VERSION ""

NS_ :

BS_:

BU_: BCU CCU Charger Charging_SDC DGPS DTI_Inverter Dash_Panel Debugger ECU Energy_Meter Fan_Controller_1 Fan_Controller_2 Fan_Controller_3 GR_Inverter IMD SAMM_Mag_1 SAMM_Mag_2 SAMM_ToF_1 SAMM_ToF_2 TCM TireTemp_FL TireTemp_FR TireTemp_RL TireTemp_RR ALL

BO_ 2147680257 BCU_Debug_2_0_to_Debugger: 8 BCU
 SG_ Debug : 0|64@1- (1,0) [0|0] "" Debugger

BO_ 2147680769 BCU_Ping_to_Debugger: 4 BCU
 SG_ Timestamp : 0|32@1+ (1,0) [0|4,294,967,296] "ms" Debugger

BO_ 2147680770 BCU_Ping_to_ECU: 4 BCU
 SG_ Timestamp : 0|32@1+ (1,0) [0|4,294,967,296] "ms" ECU

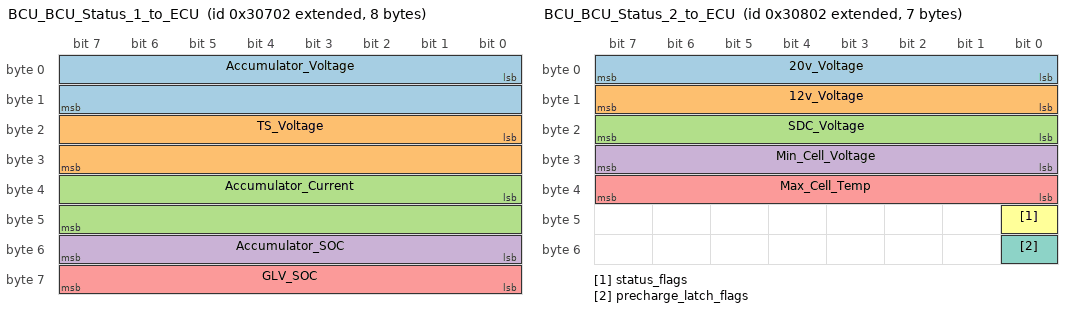
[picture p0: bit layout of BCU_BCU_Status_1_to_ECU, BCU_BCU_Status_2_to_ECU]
BO_ 2147682050 BCU_BCU_Status_1_to_ECU: 8 BCU
 SG_ Accumulator_Voltage : 0|16@1+ (0.01,0) [0|655.35] "Volts" ECU
 SG_ TS_Voltage : 16|16@1+ (0.01,0) [0|655.35] "Volts" ECU
 SG_ Accumulator_Current : 32|16@1- (0.01,0) [-327.68|327.67] "Amps" ECU
 SG_ Accumulator_SOC : 48|8@1+ (0.392157,0) [0|100] "%" ECU
 SG_ GLV_SOC : 56|8@1+ (0.392157,0) [0|100] "%" ECU

BO_ 2147682306 BCU_BCU_Status_2_to_ECU: 7 BCU
 SG_ 20v_Voltage : 0|8@1+ (1,0) [0|0] "" ECU
 SG_ 12v_Voltage : 8|8@1+ (1,0) [0|0] "" ECU
 SG_ SDC_Voltage : 16|8@1+ (1,0) [0|0] "" ECU
 SG_ Min_Cell_Voltage : 24|8@1+ (1,0) [0|0] "" ECU
 SG_ Max_Cell_Temp : 32|8@1+ (1,0) [0|0] "" ECU
 SG_ status_flags : 40|1@1+ (1,0) [0|0] "" ECU
 SG_ precharge_latch_flags : 48|1@1+ (1,0) [0|0] "" ECU

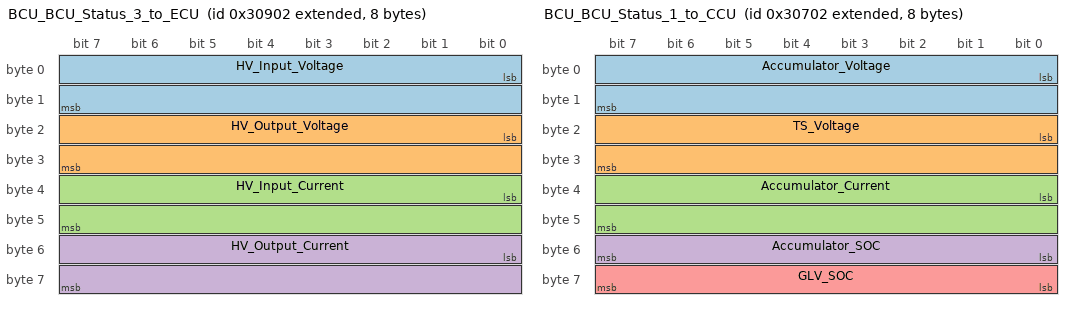
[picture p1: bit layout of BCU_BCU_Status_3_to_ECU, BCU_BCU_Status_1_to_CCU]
BO_ 2147682562 BCU_BCU_Status_3_to_ECU: 8 BCU
 SG_ HV_Input_Voltage : 0|16@1+ (0.01,0) [0|655.35] "Volts" ECU
 SG_ HV_Output_Voltage : 16|16@1+ (0.01,0) [0|655.35] "Volts" ECU
 SG_ HV_Input_Current : 32|16@1+ (0.001,0) [0|65.535] "Amps" ECU
 SG_ HV_Output_Current : 48|16@1+ (0.001,0) [0|65.535] "Amps" ECU

BO_ 2147680513 BCU_Debug_FD_to_Debugger: 64 BCU
 SG_ Debug : 0|64@1- (1,0) [0|0] "" Debugger

BO_ 2147680769 BCU_Ping_to_Debugger: 4 BCU
 SG_ Timestamp : 0|32@1+ (1,0) [0|4,294,967,296] "ms" Debugger

BO_ 2147680770 BCU_Ping_to_ECU: 4 BCU
 SG_ Timestamp : 0|32@1+ (1,0) [0|4,294,967,296] "ms" ECU

BO_ 2147683586 BCU_BCU_Cell_Data_1_to_ECU: 64 BCU
 SG_ Cell_0_Voltage : 0|8@1+ (0.01,2) [2|4.55] "Volts" ECU
 SG_ Cell_0_Temp : 8|8@1+ (0.25,0) [0|63.75] "Celsius" ECU
 SG_ Cell_1_Voltage : 16|8@1+ (0.01,2) [2|4.55] "Volts" ECU
 SG_ Cell_1_Temp : 24|8@1+ (0.25,0) [0|63.75] "Celsius" ECU
 SG_ Cell_2_Voltage : 32|8@1+ (0.01,2) [2|4.55] "Volts" ECU
 SG_ Cell_2_Temp : 40|8@1+ (0.25,0) [0|63.75] "Celsius" ECU
 SG_ Cell_3_Voltage : 48|8@1+ (0.01,2) [2|4.55] "Volts" ECU
 SG_ Cell_3_Temp : 56|8@1+ (0.25,0) [0|63.75] "Celsius" ECU
 SG_ Cell_4_Voltage : 64|8@1+ (0.01,2) [2|4.55] "Volts" ECU
 SG_ Cell_4_Temp : 72|8@1+ (0.25,0) [0|63.75] "Celsius" ECU
 SG_ Cell_5_Voltage : 80|8@1+ (0.01,2) [2|4.55] "Volts" ECU
 SG_ Cell_5_Temp : 88|8@1+ (0.25,0) [0|63.75] "Celsius" ECU
 SG_ Cell_6_Voltage : 96|8@1+ (0.01,2) [2|4.55] "Volts" ECU
 SG_ Cell_6_Temp : 104|8@1+ (0.25,0) [0|63.75] "Celsius" ECU
 SG_ Cell_7_Voltage : 112|8@1+ (0.01,2) [2|4.55] "Volts" ECU
 SG_ Cell_7_Temp : 120|8@1+ (0.25,0) [0|63.75] "Celsius" ECU
 SG_ Cell_8_Voltage : 128|8@1+ (0.01,2) [2|4.55] "Volts" ECU
 SG_ Cell_8_Temp : 136|8@1+ (0.25,0) [0|63.75] "Celsius" ECU
 SG_ Cell_9_Voltage : 144|8@1+ (0.01,2) [2|4.55] "Volts" ECU
 SG_ Cell_9_Temp : 152|8@1+ (0.25,0) [0|63.75] "Celsius" ECU
 SG_ Cell_10_Voltage : 160|8@1+ (0.01,2) [2|4.55] "Volts" ECU
 SG_ Cell_10_Temp : 168|8@1+ (0.25,0) [0|63.75] "Celsius" ECU
 SG_ Cell_11_Voltage : 176|8@1+ (0.01,2) [2|4.55] "Volts" ECU
 SG_ Cell_11_Temp : 184|8@1+ (0.25,0) [0|63.75] "Celsius" ECU
 SG_ Cell_12_Voltage : 192|8@1+ (0.01,2) [2|4.55] "Volts" ECU
 SG_ Cell_12_Temp : 200|8@1+ (0.25,0) [0|63.75] "Celsius" ECU
 SG_ Cell_13_Voltage : 208|8@1+ (0.01,2) [2|4.55] "Volts" ECU
 SG_ Cell_13_Temp : 216|8@1+ (0.25,0) [0|63.75] "Celsius" ECU
 SG_ Cell_14_Voltage : 224|8@1+ (0.01,2) [2|4.55] "Volts" ECU
 SG_ Cell_14_Temp : 232|8@1+ (0.25,0) [0|63.75] "Celsius" ECU
 SG_ Cell_15_Voltage : 240|8@1+ (0.01,2) [2|4.55] "Volts" ECU
 SG_ Cell_15_Temp : 248|8@1+ (0.25,0) [0|63.75] "Celsius" ECU
 SG_ Cell_16_Voltage : 256|8@1+ (0.01,2) [2|4.55] "Volts" ECU
 SG_ Cell_16_Temp : 264|8@1+ (0.25,0) [0|63.75] "Celsius" ECU
 SG_ Cell_17_Voltage : 272|8@1+ (0.01,2) [2|4.55] "Volts" ECU
 SG_ Cell_17_Temp : 280|8@1+ (0.25,0) [0|63.75] "Celsius" ECU
 SG_ Cell_18_Voltage : 288|8@1+ (0.01,2) [2|4.55] "Volts" ECU
 SG_ Cell_18_Temp : 296|8@1+ (0.25,0) [0|63.75] "Celsius" ECU
 SG_ Cell_19_Voltage : 304|8@1+ (0.01,2) [2|4.55] "Volts" ECU
 SG_ Cell_19_Temp : 312|8@1+ (0.25,0) [0|63.75] "Celsius" ECU
 SG_ Cell_20_Voltage : 320|8@1+ (0.01,2) [2|4.55] "Volts" ECU
 SG_ Cell_20_Temp : 328|8@1+ (0.25,0) [0|63.75] "Celsius" ECU
 SG_ Cell_21_Voltage : 336|8@1+ (0.01,2) [2|4.55] "Volts" ECU
 SG_ Cell_21_Temp : 344|8@1+ (0.25,0) [0|63.75] "Celsius" ECU
 SG_ Cell_22_Voltage : 352|8@1+ (0.01,2) [2|4.55] "Volts" ECU
 SG_ Cell_22_Temp : 360|8@1+ (0.25,0) [0|63.75] "Celsius" ECU
 SG_ Cell_23_Voltage : 368|8@1+ (0.01,2) [2|4.55] "Volts" ECU
 SG_ Cell_23_Temp : 376|8@1+ (0.25,0) [0|63.75] "Celsius" ECU
 SG_ Cell_24_Voltage : 384|8@1+ (0.01,2) [2|4.55] "Volts" ECU
 SG_ Cell_24_Temp : 392|8@1+ (0.25,0) [0|63.75] "Celsius" ECU
 SG_ Cell_25_Voltage : 400|8@1+ (0.01,2) [2|4.55] "Volts" ECU
 SG_ Cell_25_Temp : 408|8@1+ (0.25,0) [0|63.75] "Celsius" ECU
 SG_ Cell_26_Voltage : 416|8@1+ (0.01,2) [2|4.55] "Volts" ECU
 SG_ Cell_26_Temp : 424|8@1+ (0.25,0) [0|63.75] "Celsius" ECU
 SG_ Cell_27_Voltage : 432|8@1+ (0.01,2) [2|4.55] "Volts" ECU
 SG_ Cell_27_Temp : 440|8@1+ (0.25,0) [0|63.75] "Celsius" ECU
 SG_ Cell_28_Voltage : 448|8@1+ (0.01,2) [2|4.55] "Volts" ECU
 SG_ Cell_28_Temp : 456|8@1+ (0.25,0) [0|63.75] "Celsius" ECU
 SG_ Cell_29_Voltage : 464|8@1+ (0.01,2) [2|4.55] "Volts" ECU
 SG_ Cell_29_Temp : 472|8@1+ (0.25,0) [0|63.75] "Celsius" ECU
 SG_ Cell_30_Voltage : 480|8@1+ (0.01,2) [2|4.55] "Volts" ECU
 SG_ Cell_30_Temp : 488|8@1+ (0.25,0) [0|63.75] "Celsius" ECU
 SG_ Cell_31_Voltage : 496|8@1+ (0.01,2) [2|4.55] "Volts" ECU
 SG_ Cell_31_Temp : 504|8@1+ (0.25,0) [0|63.75] "Celsius" ECU

BO_ 2147683842 BCU_BCU_Cell_Data_2_to_ECU: 64 BCU
 SG_ Cell_32_Voltage : 0|8@1+ (0.01,2) [2|4.55] "Volts" ECU
 SG_ Cell_32_Temp : 8|8@1+ (0.25,0) [0|63.75] "Celsius" ECU
 SG_ Cell_33_Voltage : 16|8@1+ (0.01,2) [2|4.55] "Volts" ECU
 SG_ Cell_33_Temp : 24|8@1+ (0.25,0) [0|63.75] "Celsius" ECU
 SG_ Cell_34_Voltage : 32|8@1+ (0.01,2) [2|4.55] "Volts" ECU
 SG_ Cell_34_Temp : 40|8@1+ (0.25,0) [0|63.75] "Celsius" ECU
 SG_ Cell_35_Voltage : 48|8@1+ (0.01,2) [2|4.55] "Volts" ECU
 SG_ Cell_35_Temp : 56|8@1+ (0.25,0) [0|63.75] "Celsius" ECU
 SG_ Cell_36_Voltage : 64|8@1+ (0.01,2) [2|4.55] "Volts" ECU
 SG_ Cell_36_Temp : 72|8@1+ (0.25,0) [0|63.75] "Celsius" ECU
 SG_ Cell_37_Voltage : 80|8@1+ (0.01,2) [2|4.55] "Volts" ECU
 SG_ Cell_37_Temp : 88|8@1+ (0.25,0) [0|63.75] "Celsius" ECU
 SG_ Cell_38_Voltage : 96|8@1+ (0.01,2) [2|4.55] "Volts" ECU
 SG_ Cell_38_Temp : 104|8@1+ (0.25,0) [0|63.75] "Celsius" ECU
 SG_ Cell_39_Voltage : 112|8@1+ (0.01,2) [2|4.55] "Volts" ECU
 SG_ Cell_39_Temp : 120|8@1+ (0.25,0) [0|63.75] "Celsius" ECU
 SG_ Cell_40_Voltage : 128|8@1+ (0.01,2) [2|4.55] "Volts" ECU
 SG_ Cell_40_Temp : 136|8@1+ (0.25,0) [0|63.75] "Celsius" ECU
 SG_ Cell_41_Voltage : 144|8@1+ (0.01,2) [2|4.55] "Volts" ECU
 SG_ Cell_41_Temp : 152|8@1+ (0.25,0) [0|63.75] "Celsius" ECU
 SG_ Cell_42_Voltage : 160|8@1+ (0.01,2) [2|4.55] "Volts" ECU
 SG_ Cell_42_Temp : 168|8@1+ (0.25,0) [0|63.75] "Celsius" ECU
 SG_ Cell_43_Voltage : 176|8@1+ (0.01,2) [2|4.55] "Volts" ECU
 SG_ Cell_43_Temp : 184|8@1+ (0.25,0) [0|63.75] "Celsius" ECU
 SG_ Cell_44_Voltage : 192|8@1+ (0.01,2) [2|4.55] "Volts" ECU
 SG_ Cell_44_Temp : 200|8@1+ (0.25,0) [0|63.75] "Celsius" ECU
 SG_ Cell_45_Voltage : 208|8@1+ (0.01,2) [2|4.55] "Volts" ECU
 SG_ Cell_45_Temp : 216|8@1+ (0.25,0) [0|63.75] "Celsius" ECU
 SG_ Cell_46_Voltage : 224|8@1+ (0.01,2) [2|4.55] "Volts" ECU
 SG_ Cell_46_Temp : 232|8@1+ (0.25,0) [0|63.75] "Celsius" ECU
 SG_ Cell_47_Voltage : 240|8@1+ (0.01,2) [2|4.55] "Volts" ECU
 SG_ Cell_47_Temp : 248|8@1+ (0.25,0) [0|63.75] "Celsius" ECU
 SG_ Cell_48_Voltage : 256|8@1+ (0.01,2) [2|4.55] "Volts" ECU
 SG_ Cell_48_Temp : 264|8@1+ (0.25,0) [0|63.75] "Celsius" ECU
 SG_ Cell_49_Voltage : 272|8@1+ (0.01,2) [2|4.55] "Volts" ECU
 SG_ Cell_49_Temp : 280|8@1+ (0.25,0) [0|63.75] "Celsius" ECU
 SG_ Cell_50_Voltage : 288|8@1+ (0.01,2) [2|4.55] "Volts" ECU
 SG_ Cell_50_Temp : 296|8@1+ (0.25,0) [0|63.75] "Celsius" ECU
 SG_ Cell_51_Voltage : 304|8@1+ (0.01,2) [2|4.55] "Volts" ECU
 SG_ Cell_51_Temp : 312|8@1+ (0.25,0) [0|63.75] "Celsius" ECU
 SG_ Cell_52_Voltage : 320|8@1+ (0.01,2) [2|4.55] "Volts" ECU
 SG_ Cell_52_Temp : 328|8@1+ (0.25,0) [0|63.75] "Celsius" ECU
 SG_ Cell_53_Voltage : 336|8@1+ (0.01,2) [2|4.55] "Volts" ECU
 SG_ Cell_53_Temp : 344|8@1+ (0.25,0) [0|63.75] "Celsius" ECU
 SG_ Cell_54_Voltage : 352|8@1+ (0.01,2) [2|4.55] "Volts" ECU
 SG_ Cell_54_Temp : 360|8@1+ (0.25,0) [0|63.75] "Celsius" ECU
 SG_ Cell_55_Voltage : 368|8@1+ (0.01,2) [2|4.55] "Volts" ECU
 SG_ Cell_55_Temp : 376|8@1+ (0.25,0) [0|63.75] "Celsius" ECU
 SG_ Cell_56_Voltage : 384|8@1+ (0.01,2) [2|4.55] "Volts" ECU
 SG_ Cell_56_Temp : 392|8@1+ (0.25,0) [0|63.75] "Celsius" ECU
 SG_ Cell_57_Voltage : 400|8@1+ (0.01,2) [2|4.55] "Volts" ECU
 SG_ Cell_57_Temp : 408|8@1+ (0.25,0) [0|63.75] "Celsius" ECU
 SG_ Cell_58_Voltage : 416|8@1+ (0.01,2) [2|4.55] "Volts" ECU
 SG_ Cell_58_Temp : 424|8@1+ (0.25,0) [0|63.75] "Celsius" ECU
 SG_ Cell_59_Voltage : 432|8@1+ (0.01,2) [2|4.55] "Volts" ECU
 SG_ Cell_59_Temp : 440|8@1+ (0.25,0) [0|63.75] "Celsius" ECU
 SG_ Cell_60_Voltage : 448|8@1+ (0.01,2) [2|4.55] "Volts" ECU
 SG_ Cell_60_Temp : 456|8@1+ (0.25,0) [0|63.75] "Celsius" ECU
 SG_ Cell_61_Voltage : 464|8@1+ (0.01,2) [2|4.55] "Volts" ECU
 SG_ Cell_61_Temp : 472|8@1+ (0.25,0) [0|63.75] "Celsius" ECU
 SG_ Cell_62_Voltage : 480|8@1+ (0.01,2) [2|4.55] "Volts" ECU
 SG_ Cell_62_Temp : 488|8@1+ (0.25,0) [0|63.75] "Celsius" ECU
 SG_ Cell_63_Voltage : 496|8@1+ (0.01,2) [2|4.55] "Volts" ECU
 SG_ Cell_63_Temp : 504|8@1+ (0.25,0) [0|63.75] "Celsius" ECU

BO_ 2147684098 BCU_BCU_Cell_Data_3_to_ECU: 64 BCU
 SG_ Cell_64_Voltage : 0|8@1+ (0.01,2) [2|4.55] "Volts" ECU
 SG_ Cell_64_Temp : 8|8@1+ (0.25,0) [0|63.75] "Celsius" ECU
 SG_ Cell_65_Voltage : 16|8@1+ (0.01,2) [2|4.55] "Volts" ECU
 SG_ Cell_65_Temp : 24|8@1+ (0.25,0) [0|63.75] "Celsius" ECU
 SG_ Cell_66_Voltage : 32|8@1+ (0.01,2) [2|4.55] "Volts" ECU
 SG_ Cell_66_Temp : 40|8@1+ (0.25,0) [0|63.75] "Celsius" ECU
 SG_ Cell_67_Voltage : 48|8@1+ (0.01,2) [2|4.55] "Volts" ECU
 SG_ Cell_67_Temp : 56|8@1+ (0.25,0) [0|63.75] "Celsius" ECU
 SG_ Cell_68_Voltage : 64|8@1+ (0.01,2) [2|4.55] "Volts" ECU
 SG_ Cell_68_Temp : 72|8@1+ (0.25,0) [0|63.75] "Celsius" ECU
 SG_ Cell_69_Voltage : 80|8@1+ (0.01,2) [2|4.55] "Volts" ECU
 SG_ Cell_69_Temp : 88|8@1+ (0.25,0) [0|63.75] "Celsius" ECU
 SG_ Cell_70_Voltage : 96|8@1+ (0.01,2) [2|4.55] "Volts" ECU
 SG_ Cell_70_Temp : 104|8@1+ (0.25,0) [0|63.75] "Celsius" ECU
 SG_ Cell_71_Voltage : 112|8@1+ (0.01,2) [2|4.55] "Volts" ECU
 SG_ Cell_71_Temp : 120|8@1+ (0.25,0) [0|63.75] "Celsius" ECU
 SG_ Cell_72_Voltage : 128|8@1+ (0.01,2) [2|4.55] "Volts" ECU
 SG_ Cell_72_Temp : 136|8@1+ (0.25,0) [0|63.75] "Celsius" ECU
 SG_ Cell_73_Voltage : 144|8@1+ (0.01,2) [2|4.55] "Volts" ECU
 SG_ Cell_73_Temp : 152|8@1+ (0.25,0) [0|63.75] "Celsius" ECU
 SG_ Cell_74_Voltage : 160|8@1+ (0.01,2) [2|4.55] "Volts" ECU
 SG_ Cell_74_Temp : 168|8@1+ (0.25,0) [0|63.75] "Celsius" ECU
 SG_ Cell_75_Voltage : 176|8@1+ (0.01,2) [2|4.55] "Volts" ECU
 SG_ Cell_75_Temp : 184|8@1+ (0.25,0) [0|63.75] "Celsius" ECU
 SG_ Cell_76_Voltage : 192|8@1+ (0.01,2) [2|4.55] "Volts" ECU
 SG_ Cell_76_Temp : 200|8@1+ (0.25,0) [0|63.75] "Celsius" ECU
 SG_ Cell_77_Voltage : 208|8@1+ (0.01,2) [2|4.55] "Volts" ECU
 SG_ Cell_77_Temp : 216|8@1+ (0.25,0) [0|63.75] "Celsius" ECU
 SG_ Cell_78_Voltage : 224|8@1+ (0.01,2) [2|4.55] "Volts" ECU
 SG_ Cell_78_Temp : 232|8@1+ (0.25,0) [0|63.75] "Celsius" ECU
 SG_ Cell_79_Voltage : 240|8@1+ (0.01,2) [2|4.55] "Volts" ECU
 SG_ Cell_79_Temp : 248|8@1+ (0.25,0) [0|63.75] "Celsius" ECU
 SG_ Cell_80_Voltage : 256|8@1+ (0.01,2) [2|4.55] "Volts" ECU
 SG_ Cell_80_Temp : 264|8@1+ (0.25,0) [0|63.75] "Celsius" ECU
 SG_ Cell_81_Voltage : 272|8@1+ (0.01,2) [2|4.55] "Volts" ECU
 SG_ Cell_81_Temp : 280|8@1+ (0.25,0) [0|63.75] "Celsius" ECU
 SG_ Cell_82_Voltage : 288|8@1+ (0.01,2) [2|4.55] "Volts" ECU
 SG_ Cell_82_Temp : 296|8@1+ (0.25,0) [0|63.75] "Celsius" ECU
 SG_ Cell_83_Voltage : 304|8@1+ (0.01,2) [2|4.55] "Volts" ECU
 SG_ Cell_83_Temp : 312|8@1+ (0.25,0) [0|63.75] "Celsius" ECU
 SG_ Cell_84_Voltage : 320|8@1+ (0.01,2) [2|4.55] "Volts" ECU
 SG_ Cell_84_Temp : 328|8@1+ (0.25,0) [0|63.75] "Celsius" ECU
 SG_ Cell_85_Voltage : 336|8@1+ (0.01,2) [2|4.55] "Volts" ECU
 SG_ Cell_85_Temp : 344|8@1+ (0.25,0) [0|63.75] "Celsius" ECU
 SG_ Cell_86_Voltage : 352|8@1+ (0.01,2) [2|4.55] "Volts" ECU
 SG_ Cell_86_Temp : 360|8@1+ (0.25,0) [0|63.75] "Celsius" ECU
 SG_ Cell_87_Voltage : 368|8@1+ (0.01,2) [2|4.55] "Volts" ECU
 SG_ Cell_87_Temp : 376|8@1+ (0.25,0) [0|63.75] "Celsius" ECU
 SG_ Cell_88_Voltage : 384|8@1+ (0.01,2) [2|4.55] "Volts" ECU
 SG_ Cell_88_Temp : 392|8@1+ (0.25,0) [0|63.75] "Celsius" ECU
 SG_ Cell_89_Voltage : 400|8@1+ (0.01,2) [2|4.55] "Volts" ECU
 SG_ Cell_89_Temp : 408|8@1+ (0.25,0) [0|63.75] "Celsius" ECU
 SG_ Cell_90_Voltage : 416|8@1+ (0.01,2) [2|4.55] "Volts" ECU
 SG_ Cell_90_Temp : 424|8@1+ (0.25,0) [0|63.75] "Celsius" ECU
 SG_ Cell_91_Voltage : 432|8@1+ (0.01,2) [2|4.55] "Volts" ECU
 SG_ Cell_91_Temp : 440|8@1+ (0.25,0) [0|63.75] "Celsius" ECU
 SG_ Cell_92_Voltage : 448|8@1+ (0.01,2) [2|4.55] "Volts" ECU
 SG_ Cell_92_Temp : 456|8@1+ (0.25,0) [0|63.75] "Celsius" ECU
 SG_ Cell_93_Voltage : 464|8@1+ (0.01,2) [2|4.55] "Volts" ECU
 SG_ Cell_93_Temp : 472|8@1+ (0.25,0) [0|63.75] "Celsius" ECU
 SG_ Cell_94_Voltage : 480|8@1+ (0.01,2) [2|4.55] "Volts" ECU
 SG_ Cell_94_Temp : 488|8@1+ (0.25,0) [0|63.75] "Celsius" ECU
 SG_ Cell_95_Voltage : 496|8@1+ (0.01,2) [2|4.55] "Volts" ECU
 SG_ Cell_95_Temp : 504|8@1+ (0.25,0) [0|63.75] "Celsius" ECU

BO_ 2147684354 BCU_BCU_Cell_Data_4_to_ECU: 64 BCU
 SG_ Cell_96_Voltage : 0|8@1+ (0.01,2) [2|4.55] "Volts" ECU
 SG_ Cell_96_Temp : 8|8@1+ (0.25,0) [0|63.75] "Celsius" ECU
 SG_ Cell_97_Voltage : 16|8@1+ (0.01,2) [2|4.55] "Volts" ECU
 SG_ Cell_97_Temp : 24|8@1+ (0.25,0) [0|63.75] "Celsius" ECU
 SG_ Cell_98_Voltage : 32|8@1+ (0.01,2) [2|4.55] "Volts" ECU
 SG_ Cell_98_Temp : 40|8@1+ (0.25,0) [0|63.75] "Celsius" ECU
 SG_ Cell_99_Voltage : 48|8@1+ (0.01,2) [2|4.55] "Volts" ECU
 SG_ Cell_99_Temp : 56|8@1+ (0.25,0) [0|63.75] "Celsius" ECU
 SG_ Cell_100_Voltage : 64|8@1+ (0.01,2) [2|4.55] "Volts" ECU
 SG_ Cell_100_Temp : 72|8@1+ (0.25,0) [0|63.75] "Celsius" ECU
 SG_ Cell_101_Voltage : 80|8@1+ (0.01,2) [2|4.55] "Volts" ECU
 SG_ Cell_101_Temp : 88|8@1+ (0.25,0) [0|63.75] "Celsius" ECU
 SG_ Cell_102_Voltage : 96|8@1+ (0.01,2) [2|4.55] "Volts" ECU
 SG_ Cell_102_Temp : 104|8@1+ (0.25,0) [0|63.75] "Celsius" ECU
 SG_ Cell_103_Voltage : 112|8@1+ (0.01,2) [2|4.55] "Volts" ECU
 SG_ Cell_103_Temp : 120|8@1+ (0.25,0) [0|63.75] "Celsius" ECU
 SG_ Cell_104_Voltage : 128|8@1+ (0.01,2) [2|4.55] "Volts" ECU
 SG_ Cell_104_Temp : 136|8@1+ (0.25,0) [0|63.75] "Celsius" ECU
 SG_ Cell_105_Voltage : 144|8@1+ (0.01,2) [2|4.55] "Volts" ECU
 SG_ Cell_105_Temp : 152|8@1+ (0.25,0) [0|63.75] "Celsius" ECU
 SG_ Cell_106_Voltage : 160|8@1+ (0.01,2) [2|4.55] "Volts" ECU
 SG_ Cell_106_Temp : 168|8@1+ (0.25,0) [0|63.75] "Celsius" ECU
 SG_ Cell_107_Voltage : 176|8@1+ (0.01,2) [2|4.55] "Volts" ECU
 SG_ Cell_107_Temp : 184|8@1+ (0.25,0) [0|63.75] "Celsius" ECU
 SG_ Cell_108_Voltage : 192|8@1+ (0.01,2) [2|4.55] "Volts" ECU
 SG_ Cell_108_Temp : 200|8@1+ (0.25,0) [0|63.75] "Celsius" ECU
 SG_ Cell_109_Voltage : 208|8@1+ (0.01,2) [2|4.55] "Volts" ECU
 SG_ Cell_109_Temp : 216|8@1+ (0.25,0) [0|63.75] "Celsius" ECU
 SG_ Cell_110_Voltage : 224|8@1+ (0.01,2) [2|4.55] "Volts" ECU
 SG_ Cell_110_Temp : 232|8@1+ (0.25,0) [0|63.75] "Celsius" ECU
 SG_ Cell_111_Voltage : 240|8@1+ (0.01,2) [2|4.55] "Volts" ECU
 SG_ Cell_111_Temp : 248|8@1+ (0.25,0) [0|63.75] "Celsius" ECU
 SG_ Cell_112_Voltage : 256|8@1+ (0.01,2) [2|4.55] "Volts" ECU
 SG_ Cell_112_Temp : 264|8@1+ (0.25,0) [0|63.75] "Celsius" ECU
 SG_ Cell_113_Voltage : 272|8@1+ (0.01,2) [2|4.55] "Volts" ECU
 SG_ Cell_113_Temp : 280|8@1+ (0.25,0) [0|63.75] "Celsius" ECU
 SG_ Cell_114_Voltage : 288|8@1+ (0.01,2) [2|4.55] "Volts" ECU
 SG_ Cell_114_Temp : 296|8@1+ (0.25,0) [0|63.75] "Celsius" ECU
 SG_ Cell_115_Voltage : 304|8@1+ (0.01,2) [2|4.55] "Volts" ECU
 SG_ Cell_115_Temp : 312|8@1+ (0.25,0) [0|63.75] "Celsius" ECU
 SG_ Cell_116_Voltage : 320|8@1+ (0.01,2) [2|4.55] "Volts" ECU
 SG_ Cell_116_Temp : 328|8@1+ (0.25,0) [0|63.75] "Celsius" ECU
 SG_ Cell_117_Voltage : 336|8@1+ (0.01,2) [2|4.55] "Volts" ECU
 SG_ Cell_117_Temp : 344|8@1+ (0.25,0) [0|63.75] "Celsius" ECU
 SG_ Cell_118_Voltage : 352|8@1+ (0.01,2) [2|4.55] "Volts" ECU
 SG_ Cell_118_Temp : 360|8@1+ (0.25,0) [0|63.75] "Celsius" ECU
 SG_ Cell_119_Voltage : 368|8@1+ (0.01,2) [2|4.55] "Volts" ECU
 SG_ Cell_119_Temp : 376|8@1+ (0.25,0) [0|63.75] "Celsius" ECU
 SG_ Cell_120_Voltage : 384|8@1+ (0.01,2) [2|4.55] "Volts" ECU
 SG_ Cell_120_Temp : 392|8@1+ (0.25,0) [0|63.75] "Celsius" ECU
 SG_ Cell_121_Voltage : 400|8@1+ (0.01,2) [2|4.55] "Volts" ECU
 SG_ Cell_121_Temp : 408|8@1+ (0.25,0) [0|63.75] "Celsius" ECU
 SG_ Cell_122_Voltage : 416|8@1+ (0.01,2) [2|4.55] "Volts" ECU
 SG_ Cell_122_Temp : 424|8@1+ (0.25,0) [0|63.75] "Celsius" ECU
 SG_ Cell_123_Voltage : 432|8@1+ (0.01,2) [2|4.55] "Volts" ECU
 SG_ Cell_123_Temp : 440|8@1+ (0.25,0) [0|63.75] "Celsius" ECU
 SG_ Cell_124_Voltage : 448|8@1+ (0.01,2) [2|4.55] "Volts" ECU
 SG_ Cell_124_Temp : 456|8@1+ (0.25,0) [0|63.75] "Celsius" ECU
 SG_ Cell_125_Voltage : 464|8@1+ (0.01,2) [2|4.55] "Volts" ECU
 SG_ Cell_125_Temp : 472|8@1+ (0.25,0) [0|63.75] "Celsius" ECU
 SG_ Cell_126_Voltage : 480|8@1+ (0.01,2) [2|4.55] "Volts" ECU
 SG_ Cell_126_Temp : 488|8@1+ (0.25,0) [0|63.75] "Celsius" ECU
 SG_ Cell_127_Voltage : 496|8@1+ (0.01,2) [2|4.55] "Volts" ECU
 SG_ Cell_127_Temp : 504|8@1+ (0.25,0) [0|63.75] "Celsius" ECU

BO_ 2147684610 BCU_BCU_Cell_Data_5_to_ECU: 64 BCU
 SG_ Cell_128_Voltage : 0|8@1+ (0.01,2) [2|4.55] "Volts" ECU
 SG_ Cell_128_Temp : 8|8@1+ (0.25,0) [0|63.75] "Celsius" ECU
 SG_ Cell_129_Voltage : 16|8@1+ (0.01,2) [2|4.55] "Volts" ECU
 SG_ Cell_129_Temp : 24|8@1+ (0.25,0) [0|63.75] "Celsius" ECU
 SG_ Cell_130_Voltage : 32|8@1+ (0.01,2) [2|4.55] "Volts" ECU
 SG_ Cell_130_Temp : 40|8@1+ (0.25,0) [0|63.75] "Celsius" ECU
 SG_ Cell_131_Voltage : 48|8@1+ (0.01,2) [2|4.55] "Volts" ECU
 SG_ Cell_131_Temp : 56|8@1+ (0.25,0) [0|63.75] "Celsius" ECU
 SG_ Cell_132_Voltage : 64|8@1+ (0.01,2) [2|4.55] "Volts" ECU
 SG_ Cell_132_Temp : 72|8@1+ (0.25,0) [0|63.75] "Celsius" ECU
 SG_ Cell_133_Voltage : 80|8@1+ (0.01,2) [2|4.55] "Volts" ECU
 SG_ Cell_133_Temp : 88|8@1+ (0.25,0) [0|63.75] "Celsius" ECU
 SG_ Cell_134_Voltage : 96|8@1+ (0.01,2) [2|4.55] "Volts" ECU
 SG_ Cell_134_Temp : 104|8@1+ (0.25,0) [0|63.75] "Celsius" ECU
 SG_ Cell_135_Voltage : 112|8@1+ (0.01,2) [2|4.55] "Volts" ECU
 SG_ Cell_135_Temp : 120|8@1+ (0.25,0) [0|63.75] "Celsius" ECU
 SG_ Cell_136_Voltage : 128|8@1+ (0.01,2) [2|4.55] "Volts" ECU
 SG_ Cell_136_Temp : 136|8@1+ (0.25,0) [0|63.75] "Celsius" ECU
 SG_ Cell_137_Voltage : 144|8@1+ (0.01,2) [2|4.55] "Volts" ECU
 SG_ Cell_137_Temp : 152|8@1+ (0.25,0) [0|63.75] "Celsius" ECU
 SG_ Cell_138_Voltage : 160|8@1+ (0.01,2) [2|4.55] "Volts" ECU
 SG_ Cell_138_Temp : 168|8@1+ (0.25,0) [0|63.75] "Celsius" ECU
 SG_ Cell_139_Voltage : 176|8@1+ (0.01,2) [2|4.55] "Volts" ECU
 SG_ Cell_139_Temp : 184|8@1+ (0.25,0) [0|63.75] "Celsius" ECU
 SG_ Cell_140_Voltage : 192|8@1+ (0.01,2) [2|4.55] "Volts" ECU
 SG_ Cell_140_Temp : 200|8@1+ (0.25,0) [0|63.75] "Celsius" ECU
 SG_ Cell_141_Voltage : 208|8@1+ (0.01,2) [2|4.55] "Volts" ECU
 SG_ Cell_141_Temp : 216|8@1+ (0.25,0) [0|63.75] "Celsius" ECU
 SG_ Cell_142_Voltage : 224|8@1+ (0.01,2) [2|4.55] "Volts" ECU
 SG_ Cell_142_Temp : 232|8@1+ (0.25,0) [0|63.75] "Celsius" ECU
 SG_ Cell_143_Voltage : 240|8@1+ (0.01,2) [2|4.55] "Volts" ECU
 SG_ Cell_143_Temp : 248|8@1+ (0.25,0) [0|63.75] "Celsius" ECU
 SG_ Cell_144_Voltage : 256|8@1+ (0.01,2) [2|4.55] "Volts" ECU
 SG_ Cell_144_Temp : 264|8@1+ (0.25,0) [0|63.75] "Celsius" ECU
 SG_ Cell_145_Voltage : 272|8@1+ (0.01,2) [2|4.55] "Volts" ECU
 SG_ Cell_145_Temp : 280|8@1+ (0.25,0) [0|63.75] "Celsius" ECU
 SG_ Cell_146_Voltage : 288|8@1+ (0.01,2) [2|4.55] "Volts" ECU
 SG_ Cell_146_Temp : 296|8@1+ (0.25,0) [0|63.75] "Celsius" ECU
 SG_ Cell_147_Voltage : 304|8@1+ (0.01,2) [2|4.55] "Volts" ECU
 SG_ Cell_147_Temp : 312|8@1+ (0.25,0) [0|63.75] "Celsius" ECU
 SG_ Cell_148_Voltage : 320|8@1+ (0.01,2) [2|4.55] "Volts" ECU
 SG_ Cell_148_Temp : 328|8@1+ (0.25,0) [0|63.75] "Celsius" ECU
 SG_ Cell_149_Voltage : 336|8@1+ (0.01,2) [2|4.55] "Volts" ECU
 SG_ Cell_149_Temp : 344|8@1+ (0.25,0) [0|63.75] "Celsius" ECU
 SG_ Cell_150_Voltage : 352|8@1+ (0.01,2) [2|4.55] "Volts" ECU
 SG_ Cell_150_Temp : 360|8@1+ (0.25,0) [0|63.75] "Celsius" ECU
 SG_ Cell_151_Voltage : 368|8@1+ (0.01,2) [2|4.55] "Volts" ECU
 SG_ Cell_151_Temp : 376|8@1+ (0.25,0) [0|63.75] "Celsius" ECU
 SG_ Cell_152_Voltage : 384|8@1+ (0.01,2) [2|4.55] "Volts" ECU
 SG_ Cell_152_Temp : 392|8@1+ (0.25,0) [0|63.75] "Celsius" ECU
 SG_ Cell_153_Voltage : 400|8@1+ (0.01,2) [2|4.55] "Volts" ECU
 SG_ Cell_153_Temp : 408|8@1+ (0.25,0) [0|63.75] "Celsius" ECU
 SG_ Cell_154_Voltage : 416|8@1+ (0.01,2) [2|4.55] "Volts" ECU
 SG_ Cell_154_Temp : 424|8@1+ (0.25,0) [0|63.75] "Celsius" ECU
 SG_ Cell_155_Voltage : 432|8@1+ (0.01,2) [2|4.55] "Volts" ECU
 SG_ Cell_155_Temp : 440|8@1+ (0.25,0) [0|63.75] "Celsius" ECU
 SG_ Cell_156_Voltage : 448|8@1+ (0.01,2) [2|4.55] "Volts" ECU
 SG_ Cell_156_Temp : 456|8@1+ (0.25,0) [0|63.75] "Celsius" ECU
 SG_ Cell_157_Voltage : 464|8@1+ (0.01,2) [2|4.55] "Volts" ECU
 SG_ Cell_157_Temp : 472|8@1+ (0.25,0) [0|63.75] "Celsius" ECU
 SG_ Cell_158_Voltage : 480|8@1+ (0.01,2) [2|4.55] "Volts" ECU
 SG_ Cell_158_Temp : 488|8@1+ (0.25,0) [0|63.75] "Celsius" ECU
 SG_ Cell_159_Voltage : 496|8@1+ (0.01,2) [2|4.55] "Volts" ECU
 SG_ Cell_159_Temp : 504|8@1+ (0.25,0) [0|63.75] "Celsius" ECU

BO_ 2550588916 BCU_Charger_Control_to_Charger: 5 BCU
 SG_ Set_Voltage : 0|8@1+ (1,0) [0|0] "" Charger
 SG_ Set_Current : 16|8@1+ (1,0) [0|0] "" Charger
 SG_ Charge_Enable : 17|8@1+ (1,0) [0|0] "" Charger

BO_ 2147682050 BCU_BCU_Status_1_to_CCU: 8 BCU
 SG_ Accumulator_Voltage : 0|16@1+ (0.01,0) [0|655.35] "Volts" CCU
 SG_ TS_Voltage : 16|16@1+ (0.01,0) [0|655.35] "Volts" CCU
 SG_ Accumulator_Current : 32|16@1- (0.01,0) [-327.68|327.67] "Amps" CCU
 SG_ Accumulator_SOC : 48|8@1+ (0.392157,0) [0|100] "%" CCU
 SG_ GLV_SOC : 56|8@1+ (0.392157,0) [0|100] "%" CCU

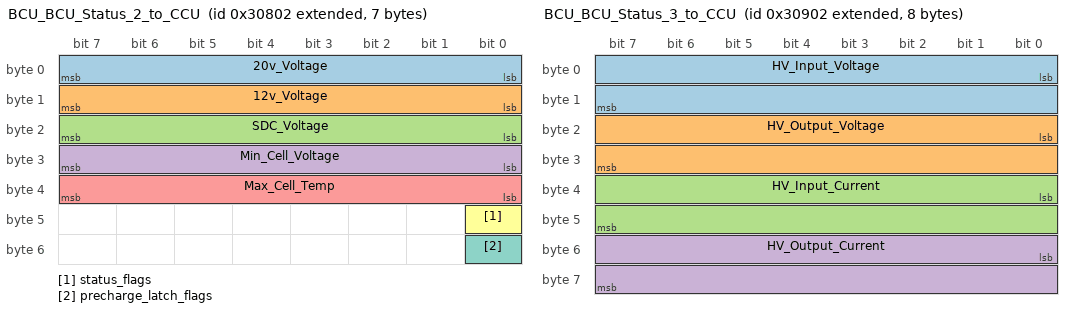
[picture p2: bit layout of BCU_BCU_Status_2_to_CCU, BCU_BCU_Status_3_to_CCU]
BO_ 2147682306 BCU_BCU_Status_2_to_CCU: 7 BCU
 SG_ 20v_Voltage : 0|8@1+ (1,0) [0|0] "" CCU
 SG_ 12v_Voltage : 8|8@1+ (1,0) [0|0] "" CCU
 SG_ SDC_Voltage : 16|8@1+ (1,0) [0|0] "" CCU
 SG_ Min_Cell_Voltage : 24|8@1+ (1,0) [0|0] "" CCU
 SG_ Max_Cell_Temp : 32|8@1+ (1,0) [0|0] "" CCU
 SG_ status_flags : 40|1@1+ (1,0) [0|0] "" CCU
 SG_ precharge_latch_flags : 48|1@1+ (1,0) [0|0] "" CCU

BO_ 2147682562 BCU_BCU_Status_3_to_CCU: 8 BCU
 SG_ HV_Input_Voltage : 0|16@1+ (0.01,0) [0|655.35] "Volts" CCU
 SG_ HV_Output_Voltage : 16|16@1+ (0.01,0) [0|655.35] "Volts" CCU
 SG_ HV_Input_Current : 32|16@1+ (0.001,0) [0|65.535] "Amps" CCU
 SG_ HV_Output_Current : 48|16@1+ (0.001,0) [0|65.535] "Amps" CCU

BO_ 2566869221 Charger_Charger_Data_to_BCU: 8 Charger
 SG_ Output_Voltage : 0|8@1+ (1,0) [0|0] "" BCU
 SG_ Output_Current : 16|8@1+ (1,0) [0|0] "" BCU
 SG_ Hardware_Failure : 17|8@1+ (1,0) [0|0] "" BCU
 SG_ OverTemp : 18|8@1+ (1,0) [0|0] "" BCU
 SG_ Input_Voltage_Error : 19|8@1+ (1,0) [0|0] "" BCU
 SG_ Connection_Error : 20|8@1+ (1,0) [0|0] "" BCU
 SG_ Communication_State : 21|8@1+ (1,0) [0|0] "" BCU

BO_ 2147811329 Dash_Panel_Debug_2_0_to_Debugger: 8 Dash_Panel
 SG_ Debug : 0|64@1- (1,0) [0|0] "" Debugger

BO_ 2147811841 Dash_Panel_Ping_to_Debugger: 4 Dash_Panel
 SG_ Timestamp : 0|32@1+ (1,0) [0|4,294,967,296] "ms" Debugger

BO_ 2147811842 Dash_Panel_Ping_to_ECU: 4 Dash_Panel
 SG_ Timestamp : 0|32@1+ (1,0) [0|4,294,967,296] "ms" ECU

BO_ 2147817986 Dash_Panel_Dash_Status_to_ECU: 3 Dash_Panel
 SG_ button_flags : 0|8@1+ (1,0) [0|0] "" ECU
 SG_ led_bits : 8|8@1+ (1,0) [0|0] "" ECU

BO_ 2147549186 Debugger_Debug_2_0_to_ECU: 8 Debugger
 SG_ Debug : 0|64@1- (1,0) [0|0] "" ECU

BO_ 2147549698 Debugger_Ping_to_ECU: 4 Debugger
 SG_ Timestamp : 0|32@1+ (1,0) [0|4,294,967,296] "ms" ECU

BO_ 2147549187 Debugger_Debug_2_0_to_BCU: 8 Debugger
 SG_ Debug : 0|64@1- (1,0) [0|0] "" BCU

BO_ 2147549699 Debugger_Ping_to_BCU: 4 Debugger
 SG_ Timestamp : 0|32@1+ (1,0) [0|4,294,967,296] "ms" BCU

BO_ 2147549188 Debugger_Debug_2_0_to_TCM: 8 Debugger
 SG_ Debug : 0|64@1- (1,0) [0|0] "" TCM

BO_ 2147549700 Debugger_Ping_to_TCM: 4 Debugger
 SG_ Timestamp : 0|32@1+ (1,0) [0|4,294,967,296] "ms" TCM

BO_ 2147549189 Debugger_Debug_2_0_to_Dash_Panel: 8 Debugger
 SG_ Debug : 0|64@1- (1,0) [0|0] "" Dash_Panel

BO_ 2147549701 Debugger_Ping_to_Dash_Panel: 4 Debugger
 SG_ Timestamp : 0|32@1+ (1,0) [0|4,294,967,296] "ms" Dash_Panel

BO_ 2147549192 Debugger_Debug_2_0_to_GR_Inverter: 8 Debugger
 SG_ Debug : 0|64@1- (1,0) [0|0] "" GR_Inverter

BO_ 2147549704 Debugger_Ping_to_GR_Inverter: 4 Debugger
 SG_ Timestamp : 0|32@1+ (1,0) [0|4,294,967,296] "ms" GR_Inverter

BO_ 2147549197 Debugger_Debug_2_0_to_Fan_Controller_1: 8 Debugger
 SG_ Debug : 0|64@1- (1,0) [0|0] "" Fan_Controller_1

BO_ 2147549709 Debugger_Ping_to_Fan_Controller_1: 4 Debugger
 SG_ Timestamp : 0|32@1+ (1,0) [0|4,294,967,296] "ms" Fan_Controller_1

BO_ 2147549198 Debugger_Debug_2_0_to_Fan_Controller_2: 8 Debugger
 SG_ Debug : 0|64@1- (1,0) [0|0] "" Fan_Controller_2

BO_ 2147549710 Debugger_Ping_to_Fan_Controller_2: 4 Debugger
 SG_ Timestamp : 0|32@1+ (1,0) [0|4,294,967,296] "ms" Fan_Controller_2

BO_ 2147549199 Debugger_Debug_2_0_to_Fan_Controller_3: 8 Debugger
 SG_ Debug : 0|64@1- (1,0) [0|0] "" Fan_Controller_3

BO_ 2147549711 Debugger_Ping_to_Fan_Controller_3: 4 Debugger
 SG_ Timestamp : 0|32@1+ (1,0) [0|4,294,967,296] "ms" Fan_Controller_3

BO_ 2147549442 Debugger_Debug_FD_to_ECU: 64 Debugger
 SG_ Debug : 0|64@1- (1,0) [0|0] "" ECU

BO_ 2147549698 Debugger_Ping_to_ECU: 4 Debugger
 SG_ Timestamp : 0|32@1+ (1,0) [0|4,294,967,296] "ms" ECU

BO_ 2147549443 Debugger_Debug_FD_to_BCU: 64 Debugger
 SG_ Debug : 0|64@1- (1,0) [0|0] "" BCU

BO_ 2147549699 Debugger_Ping_to_BCU: 4 Debugger
 SG_ Timestamp : 0|32@1+ (1,0) [0|4,294,967,296] "ms" BCU

BO_ 2147549444 Debugger_Debug_FD_to_TCM: 64 Debugger
 SG_ Debug : 0|64@1- (1,0) [0|0] "" TCM

BO_ 2147549700 Debugger_Ping_to_TCM: 4 Debugger
 SG_ Timestamp : 0|32@1+ (1,0) [0|4,294,967,296] "ms" TCM

BO_ 2147549708 Debugger_Ping_to_Charging_SDC: 4 Debugger
 SG_ Timestamp : 0|32@1+ (1,0) [0|4,294,967,296] "ms" Charging_SDC

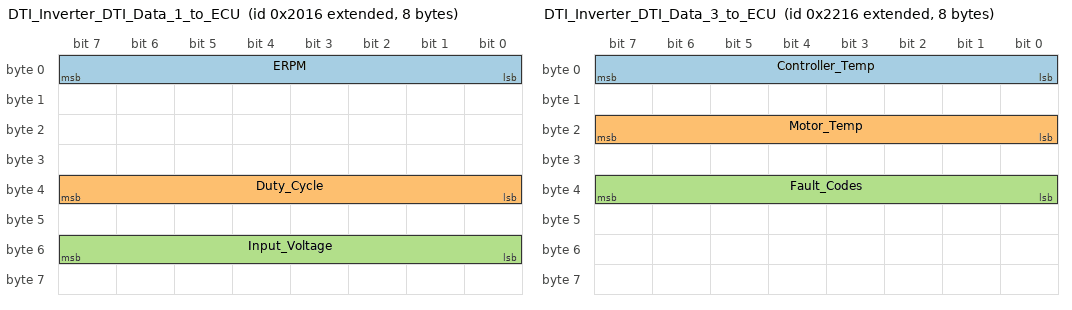
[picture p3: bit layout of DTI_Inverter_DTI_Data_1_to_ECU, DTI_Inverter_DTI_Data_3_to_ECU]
BO_ 2147491862 DTI_Inverter_DTI_Data_1_to_ECU: 8 DTI_Inverter
 SG_ ERPM : 0|8@1+ (1,0) [0|0] "" ECU
 SG_ Duty_Cycle : 32|8@1+ (1,0) [0|0] "" ECU
 SG_ Input_Voltage : 48|8@1+ (1,0) [0|0] "" ECU

BO_ 2147492118 DTI_Inverter_DTI_Data_2_to_ECU: 8 DTI_Inverter
 SG_ AC_Current : 0|8@1+ (1,0) [0|0] "" ECU
 SG_ DC_Current : 16|8@1+ (1,0) [0|0] "" ECU

BO_ 2147492374 DTI_Inverter_DTI_Data_3_to_ECU: 8 DTI_Inverter
 SG_ Controller_Temp : 0|8@1+ (1,0) [0|0] "" ECU
 SG_ Motor_Temp : 16|8@1+ (1,0) [0|0] "" ECU
 SG_ Fault_Codes : 32|8@1+ (1,0) [0|0] "" ECU

BO_ 2147492630 DTI_Inverter_DTI_Data_4_to_ECU: 8 DTI_Inverter
 SG_ FOC_Id : 0|8@1+ (1,0) [0|0] "" ECU
 SG_ FOC_Iq : 32|8@1+ (1,0) [0|0] "" ECU

BO_ 2147492886 DTI_Inverter_DTI_Data_5_to_ECU: 8 DTI_Inverter
 SG_ Throttle : 0|8@1+ (1,0) [0|0] "" ECU
 SG_ Brake : 8|8@1+ (1,0) [0|0] "" ECU
 SG_ Digital_input_1 : 16|8@1+ (1,0) [0|0] "" ECU
 SG_ Digital_input_2 : 17|8@1+ (1,0) [0|0] "" ECU
 SG_ Digital_input_3 : 18|8@1+ (1,0) [0|0] "" ECU
 SG_ Digital_input_4 : 19|8@1+ (1,0) [0|0] "" ECU
 SG_ Digital_output_1 : 20|8@1+ (1,0) [0|0] "" ECU
 SG_ Digital_output_2 : 21|8@1+ (1,0) [0|0] "" ECU
 SG_ Digital_output_3 : 22|8@1+ (1,0) [0|0] "" ECU
 SG_ Digital_output_4 : 23|8@1+ (1,0) [0|0] "" ECU
 SG_ Drive_Enable : 24|8@1+ (1,0) [0|0] "" ECU
 SG_ Capacitor_temp_limit : 32|8@1+ (1,0) [0|0] "" ECU
 SG_ DC_current_limit : 33|8@1+ (1,0) [0|0] "" ECU
 SG_ Drive_enable_limit : 34|8@1+ (1,0) [0|0] "" ECU
 SG_ IGBT_acceleration_temperature_limit : 35|8@1+ (1,0) [0|0] "" ECU
 SG_ IGBT_temperature_limit : 36|8@1+ (1,0) [0|0] "" ECU
 SG_ Input_voltage_limit : 37|8@1+ (1,0) [0|0] "" ECU
 SG_ Motor_acceleration_temperature_limit : 38|8@1+ (1,0) [0|0] "" ECU
 SG_ Motor_temperature_limit : 39|8@1+ (1,0) [0|0] "" ECU
 SG_ RPM_min_limit : 40|8@1+ (1,0) [0|0] "" ECU
 SG_ RPM_max_limit : 41|8@1+ (1,0) [0|0] "" ECU
 SG_ Power_limit : 42|8@1+ (1,0) [0|0] "" ECU
 SG_ CAN_Version : 56|8@1+ (1,0) [0|0] "" ECU

BO_ 278 ECU_DTI_Control_1_to_DTI_Inverter: 2 ECU
 SG_ Target_AC_Current : 0|8@1+ (1,0) [0|0] "" DTI_Inverter

BO_ 534 ECU_DTI_Control_2_to_DTI_Inverter: 2 ECU
 SG_ Target_Brake_Current : 0|8@1+ (1,0) [0|0] "" DTI_Inverter

BO_ 790 ECU_DTI_Control_3_to_DTI_Inverter: 4 ECU
 SG_ Target_ERPM : 0|8@1+ (1,0) [0|0] "" DTI_Inverter

BO_ 1046 ECU_DTI_Control_4_to_DTI_Inverter: 2 ECU
 SG_ Target_Position : 0|8@1+ (1,0) [0|0] "" DTI_Inverter

BO_ 1302 ECU_DTI_Control_5_to_DTI_Inverter: 2 ECU
 SG_ R_AC_Current : 0|8@1+ (1,0) [0|0] "" DTI_Inverter

BO_ 1558 ECU_DTI_Control_6_to_DTI_Inverter: 2 ECU
 SG_ R_AC_Brake_Current : 0|8@1+ (1,0) [0|0] "" DTI_Inverter

BO_ 1814 ECU_DTI_Control_7_to_DTI_Inverter: 1 ECU
 SG_ Digital_Output_1 : 0|8@1+ (1,0) [0|0] "" DTI_Inverter
 SG_ Digital_Output_2 : 1|8@1+ (1,0) [0|0] "" DTI_Inverter
 SG_ Digital_Output_3 : 2|8@1+ (1,0) [0|0] "" DTI_Inverter
 SG_ Digital_Output_4 : 3|8@1+ (1,0) [0|0] "" DTI_Inverter

BO_ 2147485718 ECU_DTI_Control_8_to_DTI_Inverter: 2 ECU
 SG_ Max_AC_Current : 0|8@1+ (1,0) [0|0] "" DTI_Inverter

BO_ 2147485974 ECU_DTI_Control_9_to_DTI_Inverter: 2 ECU
 SG_ Max_Brake_AC_Current : 0|8@1+ (1,0) [0|0] "" DTI_Inverter

BO_ 2147486230 ECU_DTI_Control_10_to_DTI_Inverter: 2 ECU
 SG_ Max_DC_Current : 0|8@1+ (1,0) [0|0] "" DTI_Inverter

BO_ 2147486486 ECU_DTI_Control_11_to_DTI_Inverter: 2 ECU
 SG_ Max_Brake_DC_Current : 0|8@1+ (1,0) [0|0] "" DTI_Inverter

BO_ 2147486742 ECU_DTI_Control_12_to_DTI_Inverter: 1 ECU
 SG_ Drive_Enable : 0|8@1+ (1,0) [0|0] "" DTI_Inverter

BO_ 2147614721 ECU_Debug_2_0_to_Debugger: 8 ECU
 SG_ Debug : 0|64@1- (1,0) [0|0] "" Debugger

BO_ 2147615233 ECU_Ping_to_Debugger: 4 ECU
 SG_ Timestamp : 0|32@1+ (1,0) [0|4,294,967,296] "ms" Debugger

BO_ 2147617283 ECU_BCU_Precharge_to_BCU: 1 ECU
 SG_ Set_TS_Active : 0|1@1+ (1,0) [0|0] "Bool" BCU

BO_ 2147617539 ECU_BCU_Config_Charge_Parameters_to_BCU: 4 ECU
 SG_ Charge_Voltage : 0|16@1+ (0.1,0) [0|6553.5] "Volts" BCU
 SG_ Charge_Current : 16|16@1+ (0.1,0) [0|6553.5] "Amps" BCU

BO_ 2147617795 ECU_BCU_Config_Operational_Parameters_to_BCU: 2 ECU
 SG_ Minimium_Cell_Voltage : 0|8@1+ (0.01,2) [2|4.55] "Volts" BCU
 SG_ Max_Cell_Temperature : 8|8@1+ (0.25,0) [0|63.75] "Celsius" BCU

BO_ 2147615235 ECU_Ping_to_BCU: 4 ECU
 SG_ Timestamp : 0|32@1+ (1,0) [0|4,294,967,296] "ms" BCU

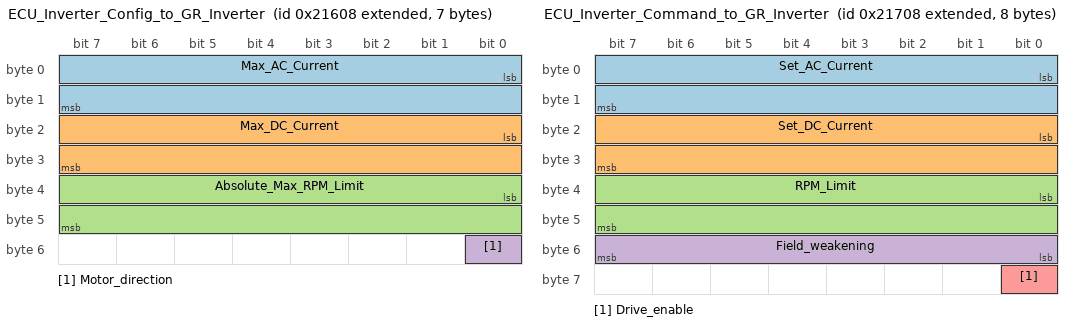
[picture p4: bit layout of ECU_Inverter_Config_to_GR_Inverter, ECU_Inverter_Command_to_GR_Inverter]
BO_ 2147620360 ECU_Inverter_Config_to_GR_Inverter: 7 ECU
 SG_ Max_AC_Current : 0|16@1+ (0.01,-327.68) [-327.68|327.67] "Amps" GR_Inverter
 SG_ Max_DC_Current : 16|16@1+ (0.01,-327.68) [-327.68|327.67] "Amps" GR_Inverter
 SG_ Absolute_Max_RPM_Limit : 32|16@1+ (1,-32768) [-32768|32767] "RPM" GR_Inverter
 SG_ Motor_direction : 48|1@1+ (1,0) ["-"|"-"] "Enable" GR_Inverter

BO_ 2147620616 ECU_Inverter_Command_to_GR_Inverter: 8 ECU
 SG_ Set_AC_Current : 0|16@1+ (0.01,-327.68) [-327.68|327.67] "Amps" GR_Inverter
 SG_ Set_DC_Current : 16|16@1+ (0.01,-327.68) [-327.68|327.67] "Amps" GR_Inverter
 SG_ RPM_Limit : 32|16@1+ (1,-32768) [-32768|32767] "RPM" GR_Inverter
 SG_ Field_weakening : 48|8@1+ (0.1,0) [0|25.5] "Amps" GR_Inverter
 SG_ Drive_enable : 56|1@1+ (1,0) ["-"|"-"] "Enable" GR_Inverter

BO_ 2147615240 ECU_Ping_to_GR_Inverter: 4 ECU
 SG_ Timestamp : 0|32@1+ (1,0) [0|4,294,967,296] "ms" GR_Inverter

BO_ 2147621133 ECU_Fan_Command_to_Fan_Controller_1: 1 ECU
 SG_ Fan_Command : 0|8@1+ (1,0) [0|255] "%" Fan_Controller_1

BO_ 2147615245 ECU_Ping_to_Fan_Controller_1: 4 ECU
 SG_ Timestamp : 0|32@1+ (1,0) [0|4,294,967,296] "ms" Fan_Controller_1

BO_ 2147621134 ECU_Fan_Command_to_Fan_Controller_2: 1 ECU
 SG_ Fan_Command : 0|8@1+ (1,0) [0|255] "%" Fan_Controller_2

BO_ 2147615246 ECU_Ping_to_Fan_Controller_2: 4 ECU
 SG_ Timestamp : 0|32@1+ (1,0) [0|4,294,967,296] "ms" Fan_Controller_2

BO_ 2147621135 ECU_Fan_Command_to_Fan_Controller_3: 1 ECU
 SG_ Fan_Command : 0|8@1+ (1,0) [0|255] "%" Fan_Controller_3

BO_ 2147615247 ECU_Ping_to_Fan_Controller_3: 4 ECU
 SG_ Timestamp : 0|32@1+ (1,0) [0|4,294,967,296] "ms" Fan_Controller_3

BO_ 2147621637 ECU_Dash_Config_to_Dash_Panel: 1 ECU
 SG_ led_bits : 0|8@1+ (1,0) [0|0] "" Dash_Panel

BO_ 2147615237 ECU_Ping_to_Dash_Panel: 4 ECU
 SG_ Timestamp : 0|32@1+ (1,0) [0|4,294,967,296] "ms" Dash_Panel

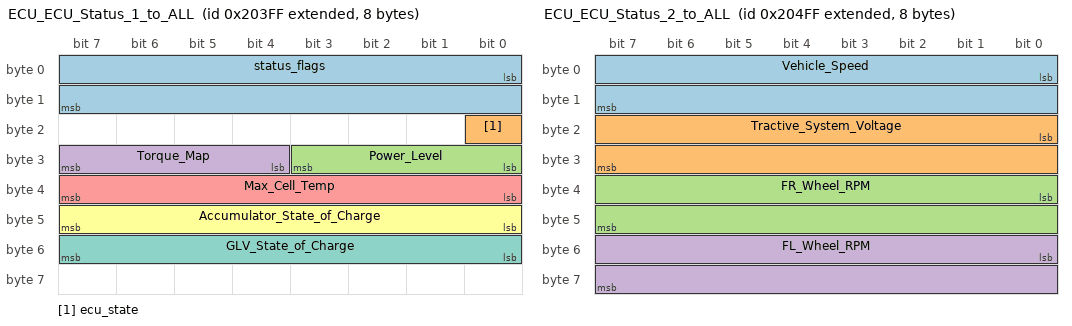
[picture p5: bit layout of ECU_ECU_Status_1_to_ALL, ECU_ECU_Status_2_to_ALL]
BO_ 2147615743 ECU_ECU_Status_1_to_ALL: 8 ECU
 SG_ status_flags : 0|16@1+ (1,0) [0|0] "" ALL
 SG_ ecu_state : 16|1@1+ (1,0) [0|0] "Bool" ALL
 SG_ Power_Level : 24|4@1+ (1,0) [0|0] "" ALL
 SG_ Torque_Map : 28|4@1+ (1,0) [0|0] "" ALL
 SG_ Max_Cell_Temp : 32|8@1+ (0.25,0) [0|63.75] "Celsius" ALL
 SG_ Accumulator_State_of_Charge : 40|8@1+ (0.392157,0) [0|100] "%" ALL
 SG_ GLV_State_of_Charge : 48|8@1+ (0.392157,0) [0|100] "%" ALL

BO_ 2147615999 ECU_ECU_Status_2_to_ALL: 8 ECU
 SG_ Vehicle_Speed : 0|16@1+ (0.01,0) [0|655.35] "MPH" ALL
 SG_ Tractive_System_Voltage : 16|16@1+ (0.01,0) [0|655.35] "Volts" ALL
 SG_ FR_Wheel_RPM : 32|16@1+ (0.1,-3276.8) [-3276.8|3276.7] "RPM" ALL
 SG_ FL_Wheel_RPM : 48|16@1+ (0.1,-3276.8) [-3276.8|3276.7] "RPM" ALL

BO_ 2147616255 ECU_ECU_Status_3_to_ALL: 4 ECU
 SG_ RR_Wheel_RPM : 0|16@1+ (0.1,-3276.8) [-3276.8|3276.7] "RPM" ALL
 SG_ RL_Wheel_RPM : 16|16@1+ (0.1,-3276.8) [-3276.8|3276.7] "RPM" ALL

BO_ 2147615236 ECU_Ping_to_TCM: 4 ECU
 SG_ Timestamp : 0|32@1+ (1,0) [0|4,294,967,296] "ms" TCM

BO_ 2147614977 ECU_Debug_FD_to_Debugger: 64 ECU
 SG_ Debug : 0|64@1- (1,0) [0|0] "" Debugger

BO_ 2147615233 ECU_Ping_to_Debugger: 4 ECU
 SG_ Timestamp : 0|32@1+ (1,0) [0|4,294,967,296] "ms" Debugger

BO_ 2147626500 ECU_ECU_Analog_Data_to_TCM: 16 ECU
 SG_ BSPD_Signal : 0|16@1+ (0.0015259,0) [0|100] "%" TCM
 SG_ BSE_Signal : 16|16@1+ (0.0015259,0) [0|100] "%" TCM
 SG_ APPS_1_Signal : 32|16@1+ (0.0015259,0) [0|100] "%" TCM
 SG_ APPS_2_Signal : 48|16@1+ (0.0015259,0) [0|100] "%" TCM
 SG_ Brakeline_F_Signal : 64|16@1+ (0.0015259,0) [0|100] "%" TCM
 SG_ Brakeline_R_Signal : 80|16@1+ (0.0015259,0) [0|100] "%" TCM
 SG_ Steering_Angle_Signal : 96|16@1+ (0.0015259,0) [0|100] "%" TCM
 SG_ AUX_Signal : 112|16@1+ (0.0015259,0) [0|100] "%" TCM

BO_ 2147626756 ECU_ECU_Performance_to_TCM: 4 ECU
 SG_ Elapsed_Cycles : 0|32@1+ (1,0) [0|0] "Clock Cycles" TCM

BO_ 2147615264 ECU_Ping_to_SAMM_Mag_1: 4 ECU
 SG_ Timestamp : 0|32@1+ (1,0) [0|4,294,967,296] "ms" SAMM_Mag_1

BO_ 2147615265 ECU_Ping_to_SAMM_Mag_2: 4 ECU
 SG_ Timestamp : 0|32@1+ (1,0) [0|4,294,967,296] "ms" SAMM_Mag_2

BO_ 2147615266 ECU_Ping_to_SAMM_ToF_1: 4 ECU
 SG_ Timestamp : 0|32@1+ (1,0) [0|4,294,967,296] "ms" SAMM_ToF_1

BO_ 2147615267 ECU_Ping_to_SAMM_ToF_2: 4 ECU
 SG_ Timestamp : 0|32@1+ (1,0) [0|4,294,967,296] "ms" SAMM_ToF_2

BO_ 2147615268 ECU_Ping_to_TireTemp_FL: 4 ECU
 SG_ Timestamp : 0|32@1+ (1,0) [0|4,294,967,296] "ms" TireTemp_FL

BO_ 2147615269 ECU_Ping_to_TireTemp_FR: 4 ECU
 SG_ Timestamp : 0|32@1+ (1,0) [0|4,294,967,296] "ms" TireTemp_FR

BO_ 2147615270 ECU_Ping_to_TireTemp_RL: 4 ECU
 SG_ Timestamp : 0|32@1+ (1,0) [0|4,294,967,296] "ms" TireTemp_RL

BO_ 2147615271 ECU_Ping_to_TireTemp_RR: 4 ECU
 SG_ Timestamp : 0|32@1+ (1,0) [0|4,294,967,296] "ms" TireTemp_RR

BO_ 269 Energy_Meter_EM_Measurement_to_BCU: 8 Energy_Meter
 SG_ Current : 0|8@1+ (1,0) [0|0] "" BCU
 SG_ Voltage : 32|8@1+ (1,0) [0|0] "" BCU

BO_ 781 Energy_Meter_EM_Team_Data_1_to_BCU: 8 Energy_Meter
 SG_ Team_Signal_1 : 0|8@1+ (1,0) [0|0] "" BCU
 SG_ Team_Signal_2 : 32|8@1+ (1,0) [0|0] "" BCU

BO_ 782 Energy_Meter_EM_Team_Data_2_to_BCU: 8 Energy_Meter
 SG_ Team_Signal_3 : 0|8@1+ (1,0) [0|0] "" BCU
 SG_ Team_Signal_4 : 32|8@1+ (1,0) [0|0] "" BCU

BO_ 1037 Energy_Meter_EM_Status_to_BCU: 8 Energy_Meter
 SG_ Violation : 0|8@1+ (1,0) [0|0] "" BCU
 SG_ Logging : 1|8@1+ (1,0) [0|0] "" BCU
 SG_ Energy : 8|8@1+ (1,0) [0|0] "" BCU

BO_ 1549 Energy_Meter_EM_Temperature_to_BCU: 8 Energy_Meter
 SG_ Mux_Signal : 0|8@1+ (1,0) [0|0] "" BCU
 SG_ Num_Sensors : 3|8@1+ (1,0) [0|0] "" BCU
 SG_ Min_Temp : 8|8@1+ (1,0) [0|0] "" BCU
 SG_ Max_Temp : 16|8@1+ (1,0) [0|0] "" BCU
 SG_ Temp_5n : 24|8@1+ (1,0) [0|0] "" BCU
 SG_ Temp_5n1 : 32|8@1+ (1,0) [0|0] "" BCU
 SG_ Temp_5n2 : 40|8@1+ (1,0) [0|0] "" BCU
 SG_ Temp_5n3 : 48|8@1+ (1,0) [0|0] "" BCU
 SG_ Temp_5n4 : 56|8@1+ (1,0) [0|0] "" BCU

BO_ 2148335617 Fan_Controller_1_Debug_2_0_to_Debugger: 8 Fan_Controller_1
 SG_ Debug : 0|64@1- (1,0) [0|0] "" Debugger

BO_ 2148336129 Fan_Controller_1_Ping_to_Debugger: 4 Fan_Controller_1
 SG_ Timestamp : 0|32@1+ (1,0) [0|4,294,967,296] "ms" Debugger

BO_ 2148336130 Fan_Controller_1_Ping_to_ECU: 4 Fan_Controller_1
 SG_ Timestamp : 0|32@1+ (1,0) [0|4,294,967,296] "ms" ECU

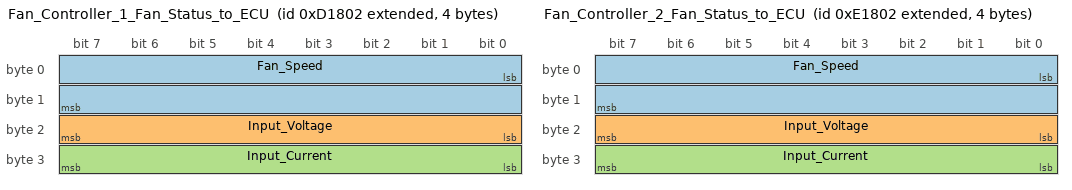
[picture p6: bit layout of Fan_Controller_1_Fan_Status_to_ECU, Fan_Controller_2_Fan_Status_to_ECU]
BO_ 2148341762 Fan_Controller_1_Fan_Status_to_ECU: 4 Fan_Controller_1
 SG_ Fan_Speed : 0|16@1+ (1,0) [0|65535] "RPM" ECU
 SG_ Input_Voltage : 16|8@1+ (0.1,0) [0|25.5] "Volts" ECU
 SG_ Input_Current : 24|8@1+ (0.1,0) [0|25.5] "Amps" ECU

BO_ 2148401153 Fan_Controller_2_Debug_2_0_to_Debugger: 8 Fan_Controller_2
 SG_ Debug : 0|64@1- (1,0) [0|0] "" Debugger

BO_ 2148401665 Fan_Controller_2_Ping_to_Debugger: 4 Fan_Controller_2
 SG_ Timestamp : 0|32@1+ (1,0) [0|4,294,967,296] "ms" Debugger

BO_ 2148401666 Fan_Controller_2_Ping_to_ECU: 4 Fan_Controller_2
 SG_ Timestamp : 0|32@1+ (1,0) [0|4,294,967,296] "ms" ECU

BO_ 2148407298 Fan_Controller_2_Fan_Status_to_ECU: 4 Fan_Controller_2
 SG_ Fan_Speed : 0|16@1+ (1,0) [0|65535] "RPM" ECU
 SG_ Input_Voltage : 16|8@1+ (0.1,0) [0|25.5] "Volts" ECU
 SG_ Input_Current : 24|8@1+ (0.1,0) [0|25.5] "Amps" ECU

BO_ 2148466689 Fan_Controller_3_Debug_2_0_to_Debugger: 8 Fan_Controller_3
 SG_ Debug : 0|64@1- (1,0) [0|0] "" Debugger

BO_ 2148467201 Fan_Controller_3_Ping_to_Debugger: 4 Fan_Controller_3
 SG_ Timestamp : 0|32@1+ (1,0) [0|4,294,967,296] "ms" Debugger

BO_ 2148467202 Fan_Controller_3_Ping_to_ECU: 4 Fan_Controller_3
 SG_ Timestamp : 0|32@1+ (1,0) [0|4,294,967,296] "ms" ECU

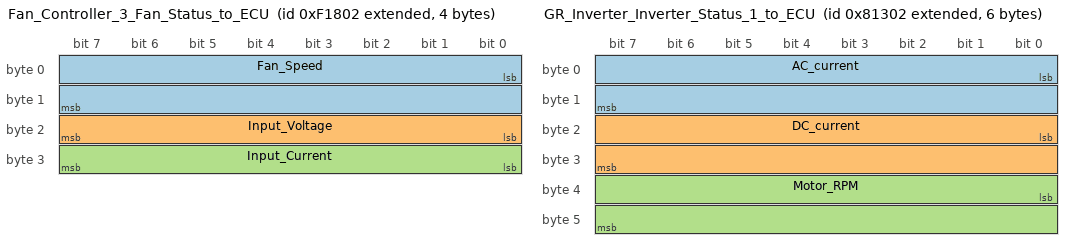
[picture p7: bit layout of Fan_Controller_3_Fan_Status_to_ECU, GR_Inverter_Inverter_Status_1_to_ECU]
BO_ 2148472834 Fan_Controller_3_Fan_Status_to_ECU: 4 Fan_Controller_3
 SG_ Fan_Speed : 0|16@1+ (1,0) [0|65535] "RPM" ECU
 SG_ Input_Voltage : 16|8@1+ (0.1,0) [0|25.5] "Volts" ECU
 SG_ Input_Current : 24|8@1+ (0.1,0) [0|25.5] "Amps" ECU

BO_ 2148007937 GR_Inverter_Debug_2_0_to_Debugger: 8 GR_Inverter
 SG_ Debug : 0|64@1- (1,0) [0|0] "" Debugger

BO_ 2148008449 GR_Inverter_Ping_to_Debugger: 4 GR_Inverter
 SG_ Timestamp : 0|32@1+ (1,0) [0|4,294,967,296] "ms" Debugger

BO_ 2148008450 GR_Inverter_Ping_to_ECU: 4 GR_Inverter
 SG_ Timestamp : 0|32@1+ (1,0) [0|4,294,967,296] "ms" ECU

BO_ 2148012802 GR_Inverter_Inverter_Status_1_to_ECU: 6 GR_Inverter
 SG_ AC_current : 0|16@1+ (0.01,-327.68) [-327.68|327.67] "Amps" ECU
 SG_ DC_current : 16|16@1+ (0.01,0) [0|655.35] "Amps" ECU
 SG_ Motor_RPM : 32|16@1+ (1,-32768) [-32768|32767] "RPM" ECU

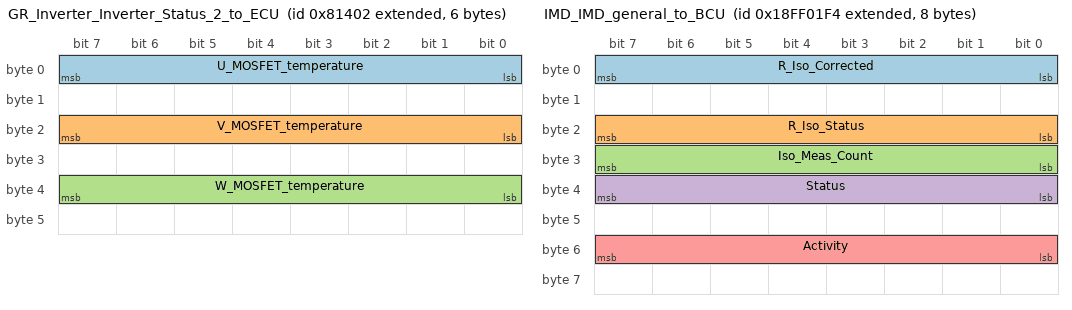
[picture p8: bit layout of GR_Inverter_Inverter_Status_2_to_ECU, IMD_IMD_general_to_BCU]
BO_ 2148013058 GR_Inverter_Inverter_Status_2_to_ECU: 6 GR_Inverter
 SG_ U_MOSFET_temperature : 0|8@1+ (1,-40) [-40|215] "Celsius" ECU
 SG_ V_MOSFET_temperature : 16|8@1+ (1,-40) [-40|215] "Celsius" ECU
 SG_ W_MOSFET_temperature : 32|8@1+ (1,-40) [-40|215] "Celsius" ECU

BO_ 2148013314 GR_Inverter_Inverter_Status_3_to_ECU: 3 GR_Inverter
 SG_ Motor_temperature : 0|8@1+ (1,-40) [-40|215] "Celsius" ECU
 SG_ fault_bits : 16|8@1+ (1,0) [0|0] "" ECU

BO_ 35 IMD_IMD_response_to_BCU: 0 IMD

BO_ 2565862654 IMD_IMD_isolation_info_to_BCU: 0 IMD

BO_ 2565862654 IMD_IMD_voltage_to_BCU: 0 IMD

BO_ 2565862654 IMD_IMD_IT_system_to_BCU: 0 IMD

BO_ 2565862654 IMD_IMD_request_to_BCU: 0 IMD

BO_ 2565862654 IMD_IMD_request_to_BCU: 0 IMD

BO_ 2566849012 IMD_IMD_general_to_BCU: 8 IMD
 SG_ R_Iso_Corrected : 0|8@1+ (1,0) [0|0] "" BCU
 SG_ R_Iso_Status : 16|8@1+ (1,0) [0|0] "" BCU
 SG_ Iso_Meas_Count : 24|8@1+ (1,0) [0|0] "" BCU
 SG_ Status : 32|8@1+ (1,0) [0|0] "" BCU
 SG_ Activity : 48|8@1+ (1,0) [0|0] "" BCU

BO_ 2147746305 TCM_Ping_to_Debugger: 4 TCM
 SG_ Timestamp : 0|32@1+ (1,0) [0|4,294,967,296] "ms" Debugger

BO_ 2147746306 TCM_Ping_to_ECU: 4 TCM
 SG_ Timestamp : 0|32@1+ (1,0) [0|4,294,967,296] "ms" ECU

BO_ 2147746305 TCM_Ping_to_Debugger: 4 TCM
 SG_ Timestamp : 0|32@1+ (1,0) [0|4,294,967,296] "ms" Debugger

BO_ 2147617283 CCU_BCU_Precharge_to_BCU: 1 CCU
 SG_ Set_TS_Active : 0|1@1+ (1,0) [0|0] "Bool" BCU

BO_ 2147614723 CCU_Debug_2_0_to_BCU: 8 CCU
 SG_ Debug : 0|64@1- (1,0) [0|0] "" BCU

BO_ 2150642436 DGPS_GPS_ALT_to_TCM: 8 DGPS
 SG_ ALT : 0|64@1+ (1,0) [0|0] "" TCM

BO_ 2150641924 DGPS_GPS_LAT_to_TCM: 8 DGPS
 SG_ LAT : 0|64@1+ (1,0) [0|0] "" TCM

BO_ 2150642180 DGPS_GPS_LON_to_TCM: 8 DGPS
 SG_ LON : 0|64@1+ (1,0) [0|0] "" TCM

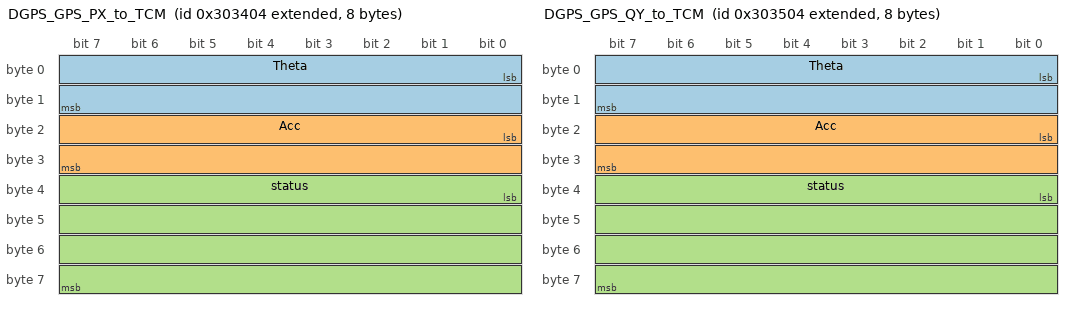
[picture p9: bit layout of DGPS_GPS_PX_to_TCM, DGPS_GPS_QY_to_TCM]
BO_ 2150642692 DGPS_GPS_PX_to_TCM: 8 DGPS
 SG_ Theta : 0|16@1- (0.001,0) [0|0] "" TCM
 SG_ Acc : 16|16@1- (0.01,0) [0|0] "" TCM
 SG_ status : 32|32@1+ (1,0) [0|0] "" TCM

BO_ 2150642948 DGPS_GPS_QY_to_TCM: 8 DGPS
 SG_ Theta : 0|16@1- (0.001,0) [0|0] "" TCM
 SG_ Acc : 16|16@1- (0.01,0) [0|0] "" TCM
 SG_ status : 32|32@1+ (1,0) [0|0] "" TCM

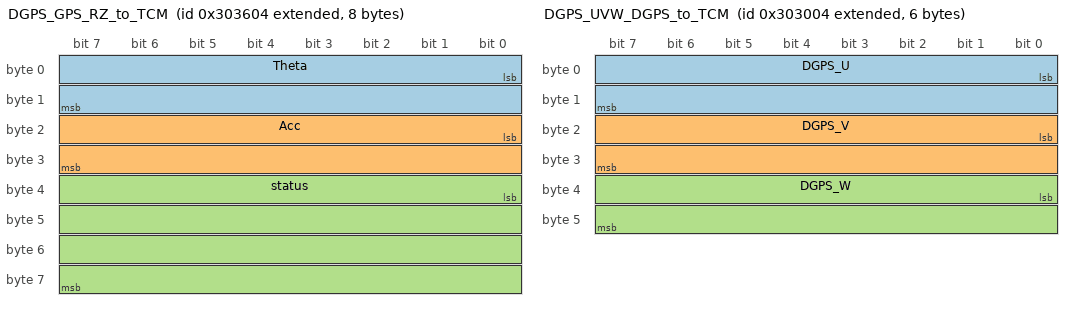
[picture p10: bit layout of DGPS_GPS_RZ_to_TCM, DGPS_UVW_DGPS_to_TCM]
BO_ 2150643204 DGPS_GPS_RZ_to_TCM: 8 DGPS
 SG_ Theta : 0|16@1- (0.001,0) [0|0] "" TCM
 SG_ Acc : 16|16@1- (0.01,0) [0|0] "" TCM
 SG_ status : 32|32@1+ (1,0) [0|0] "" TCM

BO_ 2150641668 DGPS_UVW_DGPS_to_TCM: 6 DGPS
 SG_ DGPS_U : 0|16@1- (0.01,0) [0|0] "" TCM
 SG_ DGPS_V : 16|16@1- (0.01,0) [0|0] "" TCM
 SG_ DGPS_W : 32|16@1- (0.01,0) [0|0] "" TCM

BO_ 2149581314 SAMM_Mag_1_Ping_to_ECU: 4 SAMM_Mag_1
 SG_ Timestamp : 0|32@1+ (1,0) [0|4,294,967,296] "ms" ECU

BO_ 2149646850 SAMM_Mag_2_Ping_to_ECU: 4 SAMM_Mag_2
 SG_ Timestamp : 0|32@1+ (1,0) [0|4,294,967,296] "ms" ECU

BO_ 2149712386 SAMM_ToF_1_Ping_to_ECU: 4 SAMM_ToF_1
 SG_ Timestamp : 0|32@1+ (1,0) [0|4,294,967,296] "ms" ECU

BO_ 2149777922 SAMM_ToF_2_Ping_to_ECU: 4 SAMM_ToF_2
 SG_ Timestamp : 0|32@1+ (1,0) [0|4,294,967,296] "ms" ECU

BO_ 2149843458 TireTemp_FL_Ping_to_ECU: 4 TireTemp_FL
 SG_ Timestamp : 0|32@1+ (1,0) [0|4,294,967,296] "ms" ECU

BO_ 2149908994 TireTemp_FR_Ping_to_ECU: 4 TireTemp_FR
 SG_ Timestamp : 0|32@1+ (1,0) [0|4,294,967,296] "ms" ECU

BO_ 2149974530 TireTemp_RL_Ping_to_ECU: 4 TireTemp_RL
 SG_ Timestamp : 0|32@1+ (1,0) [0|4,294,967,296] "ms" ECU

BO_ 2150040066 TireTemp_RR_Ping_to_ECU: 4 TireTemp_RR
 SG_ Timestamp : 0|32@1+ (1,0) [0|4,294,967,296] "ms" ECU
